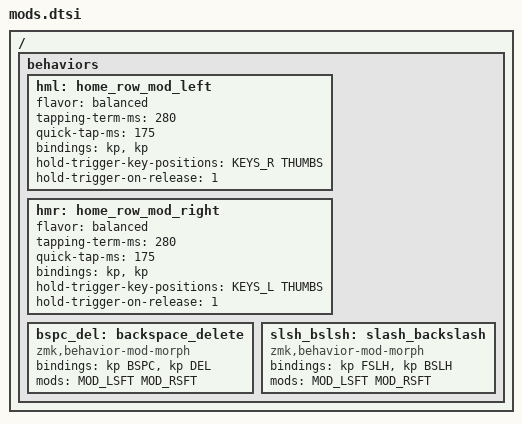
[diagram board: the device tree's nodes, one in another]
// 					                                     38 KEY MATRIX / LAYOUT MAPPING
//
//		        	╭────────────────────┬────────────────────╮              ╭─────────────────────┬─────────────────────╮ 
//			        │  0   1   2   3   4 │  5   6   7   8   9 │              │ LT4 LT3 LT2 LT1 LT0 │ RT0 RT1 RT2 RT3 RT4 │
//		         ╭──╯ 10  11  12  13  14 │ 15  16  17  18  19 ╰───╮      ╭───╯ LM4 LM3 LM2 LM1 LM0 │ RM0 RM1 RM2 RM3 RM4 ╰───╮
//		         │ 20 21  22  23  24  25 │ 26  27  28  29  30  31 │      │ LB5 LB4 LB3 LB2 LB1 LB0 │ RB0 RB1 RB2 RB3 RB4 RB5 │
//		         ╰──────────╮ 32  33  34 │ 35  36  37 ╭───────────╯      ╰───────────╮ LH2 LH1 LH0 │ RH0 RH1 RH2 ╭───────────╯
//				        	╰────────────┴────────────╯                              ╰─────────────┴─────────────╯



/* Timerless Home Row Mods */
/* https://github.com/urob/zmk-config#timeless-homerow-mods */


/ {
behaviors {
        /* left-hand HRMs */
        hml: home_row_mod_left {
            flavor = "balanced";
            tapping-term-ms = <280>;
            quick-tap-ms = <175>;
            bindings = <&kp &kp>;
            hold-trigger-key-positions = <KEYS_R THUMBS>;
            hold-trigger-on-release = <1>;
        };

        /* right-hand HRMs */
        hmr: home_row_mod_right {
            flavor = "balanced";
            tapping-term-ms = <280>;
            quick-tap-ms = <175>;
            bindings = <&kp &kp>;
            hold-trigger-key-positions = <KEYS_L THUMBS>;
            hold-trigger-on-release = <1>;
        };

        // tap: backspace | shift + tap: delete
        bspc_del: backspace_delete {
            compatible = "zmk,behavior-mod-morph";
            #binding-cells = <0>;
            bindings = <&kp BSPC>, <&kp DEL>;
            mods = <MOD_LSFT MOD_RSFT>;
        };

        // tap: slash | shift + tap: backslash
        slsh_bslsh: slash_backslash {
            compatible = "zmk,behavior-mod-morph";
            #binding-cells = <0>;
            bindings = <&kp FSLH>, <&kp BSLH>;
            mods = <MOD_LSFT MOD_RSFT>;
        };
    };
};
